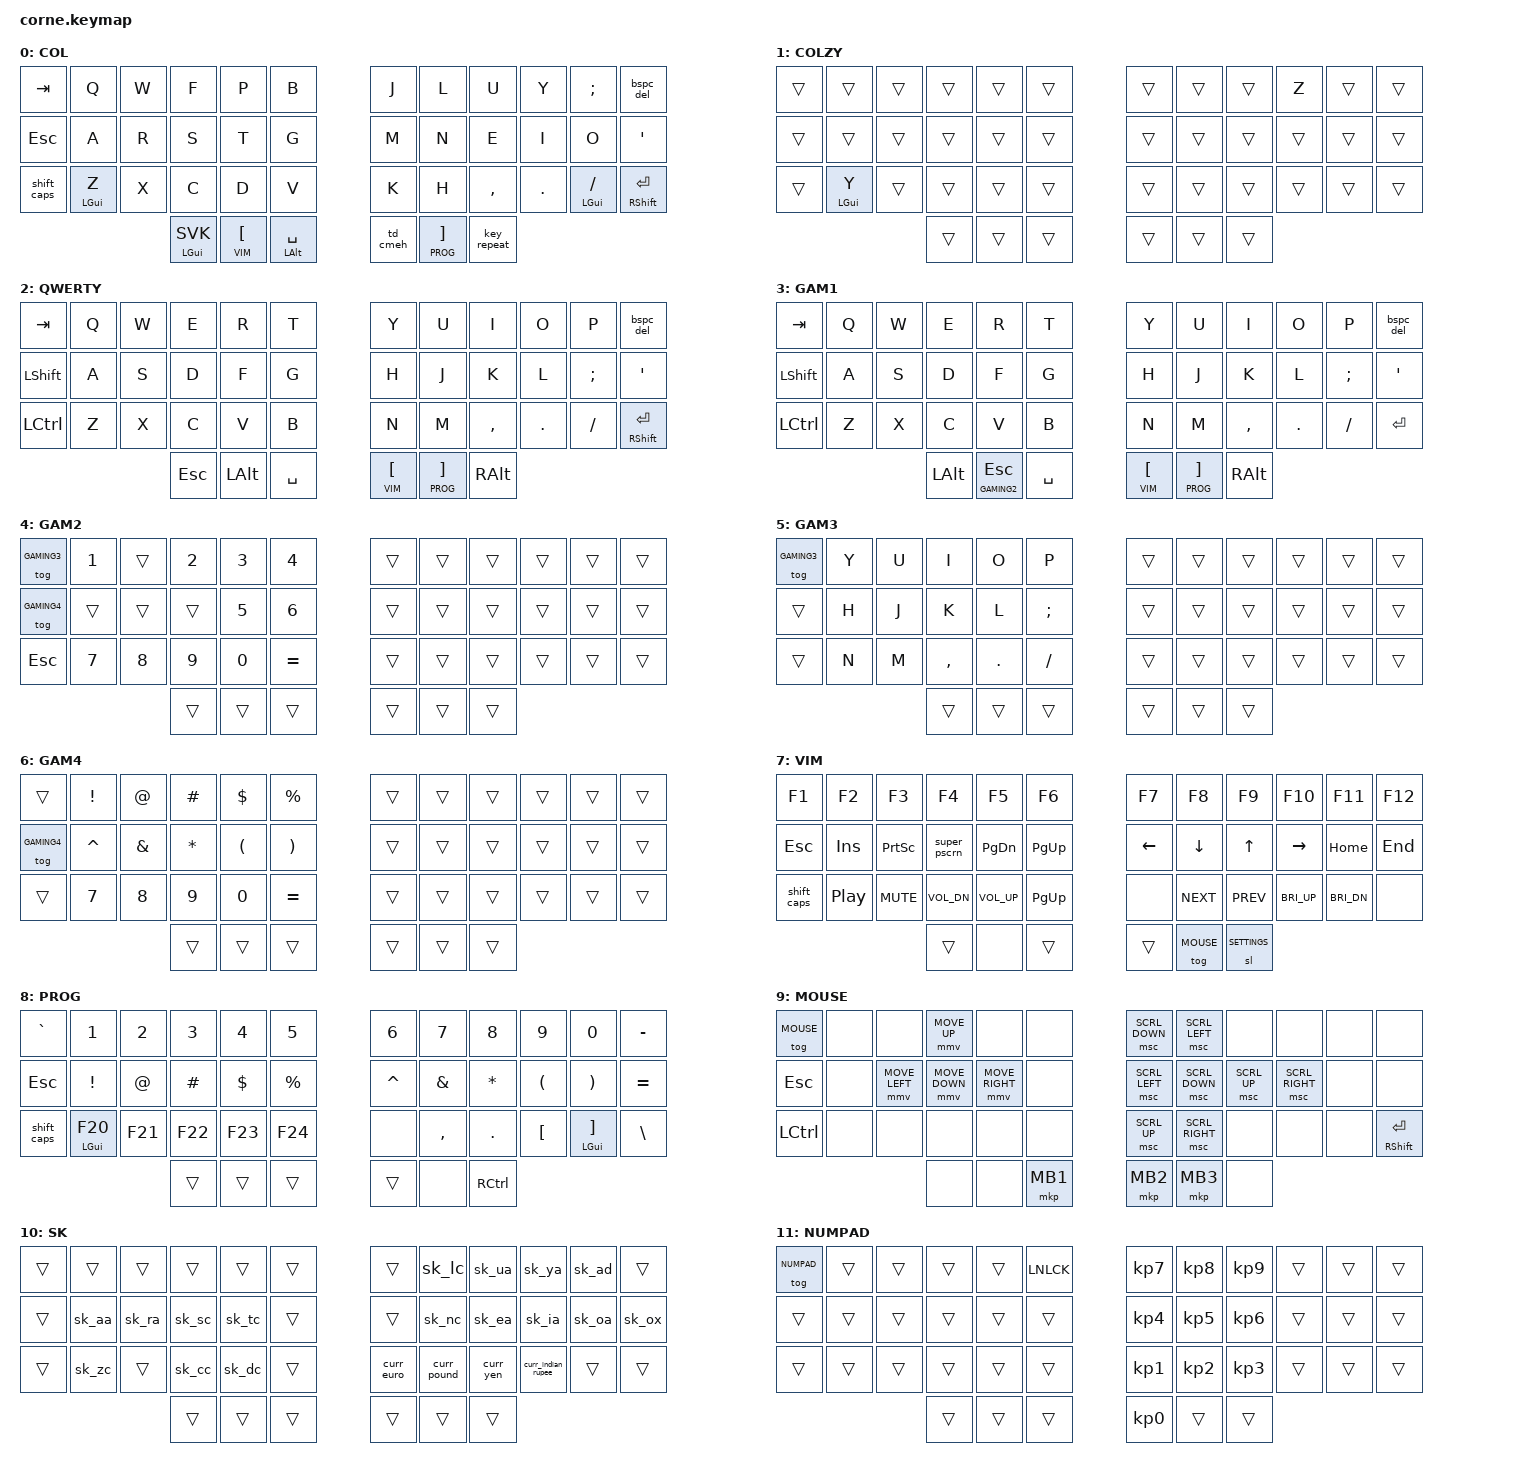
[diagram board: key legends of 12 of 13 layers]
/*
 * Copyright (c) 2020 The ZMK Contributors
 *
 * SPDX-License-Identifier: MIT
 */

/*
to visualize keymap:
https://nickcoutsos.github.io/keymap-editor/
https://github.com/caksoylar/keymap-drawer
to visualize battery without need of display
https://github.com/mh4x0f/zmkBATx
*/

#include <behaviors.dtsi>
#include <dt-bindings/zmk/keys.h>
#include <dt-bindings/zmk/bt.h>
#include <dt-bindings/zmk/outputs.h>
//#include <dt-bindings/zmk/ext_power.h>
#include <dt-bindings/zmk/outputs.h>

//#define ZMK_POINTING_DEFAULT_MOVE_VAL 1500  // default: 600
//#define ZMK_POINTING_DEFAULT_SCRL_VAL 20    // default: 10
#include <dt-bindings/zmk/pointing.h>

#define HOST_OS 1
#include "zmk-helpers/helper.h"
#include "zmk-helpers/unicode-chars/slovak.dtsi"
#include "zmk-helpers/unicode-chars/currency.dtsi"

#define COLEMAK  0
#define COLEMAKZ 1
#define QWERTY   2
#define GAMING   3
#define GAMING2  4
#define GAMING3  5
#define GAMING4  6
#define VIM      7
#define PROG     8
#define MOUSE    9
#define SVK      10
#define NUMPAD   11
#define SETTINGS 12


&mt {
      //tapping-term-ms = <1300>;
      flavor = "tap-preferred";
};

&sk {
    release-after-ms = <2500>;
    ignore-modifiers;
};

//&sl {
//    release-after-ms = <2000>;
//};

&key_repeat {
    usage-pages = <HID_USAGE_KEY HID_USAGE_CONSUMER>;
};

/ {
    behaviors {
        shift_caps: tap_dance_caps {
            compatible = "zmk,behavior-tap-dance";
            label = "TAP_DANCE_CAPS";
            #binding-cells = <0>;
            tapping-term-ms = <200>;
            bindings = <&kp LSHFT>, <&caps_word>;
        };

        td_gui: tap_dance_sticky_gui {
            compatible = "zmk,behavior-tap-dance";
            label = "TAP_DANCE_STICKY_GUI";
            #binding-cells = <0>;
            tapping-term-ms = <200>;
            bindings = <&kp LGUI>, <&sk LG(LALT)>, <&sk LG(LCTRL)>, <&sk LG(LSHIFT)>, <&sk RALT>;
        };

        td_cmeh: tap_dance_sticky_ctrl_meh {
            compatible = "zmk,behavior-tap-dance";
            label = "TAP_DANCE_STICKY_CTRL_MEH";
            #binding-cells = <0>;
            tapping-term-ms = <200>;
            bindings = <&kp LCTRL>, <&sk LG(LA(LCTRL))>, <&sk LG(LA(LS(LCTRL)))>, <&sk RALT>;
        };

        bspc_del: backspace_delete {
            compatible = "zmk,behavior-mod-morph";
            label = "BACKSPACE_DELETE";
            #binding-cells = <0>;
            bindings = <&kp BACKSPACE>, <&kp DELETE>;
            mods = <(MOD_LSFT|MOD_RSFT)>;
            keep-mods = <(MOD_RSFT)>;
        };

        mod_sl: hold_mod_sticky_layer {
            compatible = "zmk,behavior-hold-tap";
            label = "HOLD_MOD_STICKY_LAYER";
            #binding-cells = <2>;
            flavor = "hold-preferred";
            tapping-term-ms = <200>;
            bindings = <&kp>, <&sl>;
        };

        lm_sk: hold_layer_sticky_key {
            compatible = "zmk,behavior-hold-tap";
            label = "HOLD_LAYER_STICKY_KEY";
            #binding-cells = <2>;
            flavor = "hold-preferred";
            tapping-term-ms = <200>;
            bindings = <&mo>, <&sk>;
        };
    };




//SEE EXAMPLE: https://zmk.dev/docs/keymaps/behaviors/macros#layer--modifier
   macros {
        super_pscrn: super_pscrn {
            compatible = "zmk,behavior-macro";
            #binding-cells = <0>;
            bindings
                = <&macro_press &kp LGUI>
                , <&macro_tap &kp PSCRN>
                , <&macro_release &kp LGUI>
                ;
        };
   };

    //conditional_layers {
    //    compatible = "zmk,conditional-layers";
    //    to_qwerty_layer {
    //        if-layers = <COLEMAK>;
    //        then-layer = <QWERTY>;
    //    };
    //    to_colemak_layer {
    //        if-layers = <QWERTY>;
    //        then-layer = <COLEMAK>;
    //    };
    //};

    chosen {
      zmk,battery = &vbatt;
    };

    vbatt: vbatt {
        compatible = "zmk,battery-nrf-vddh";
        label = "VBATT";
    };

    keymap {
            compatible = "zmk,keymap";

                default_layer {
                        display-name = "COL";
                        bindings = <
   &kp TAB   &kp Q &kp W &kp F &kp P &kp B   &kp J &kp L  &kp U  &kp Y   &kp SEMI &bspc_del
   &kp ESC   &kp A &kp R &kp S &kp T &kp G   &kp M &kp N  &kp E  &kp I   &kp O    &kp SQT
   &shift_caps &mt LGUI Z &kp X &kp C &kp D &kp V   &kp K &kp H  &kp COMMA &kp DOT &mt LGUI FSLH &mt RSHIFT RET
             &mod_sl LGUI SVK &lt VIM LBKT &mt LALT SPACE   &td_cmeh &lt PROG RBKT &key_repeat
                        >;
                };




                colemak_qwertz_layer {
                        display-name = "COLZY";
                        bindings = <
   &trans &trans &trans &trans &trans &trans    &trans &trans &trans &kp Z &trans &trans
   &trans &trans &trans &trans &trans &trans    &trans &trans &trans &trans &trans &trans
   &trans &mt LGUI Y &trans &trans &trans &trans    &trans &trans &trans &trans &trans &trans
                     &trans &trans &trans    &trans &trans &trans
                        >;
                };




                qwerty_layer {
                        display-name = "QWERTY";
                        bindings = <
   &kp TAB   &kp Q &kp W &kp E &kp R &kp T   &kp Y &kp U  &kp I     &kp O   &kp P &bspc_del
   &kp LSHFT &kp A &kp S &kp D &kp F &kp G   &kp H &kp J  &kp K     &kp L   &kp SEMI &kp SQT
   &kp LCTRL &kp Z &kp X &kp C &kp V &kp B   &kp N &kp M  &kp COMMA &kp DOT &kp FSLH &mt RSHIFT RET
             &kp ESC &kp LALT &kp SPACE   &lt VIM LBKT &lt PROG RBKT &kp RALT
                        >;
                };




                gaming_layer {
                        display-name = "GAM1";
                        bindings = <
   &kp TAB   &kp Q &kp W &kp E &kp R &kp T   &kp Y &kp U  &kp I     &kp O   &kp P &bspc_del
   &kp LSHFT &kp A &kp S &kp D &kp F &kp G   &kp H &kp J  &kp K     &kp L   &kp SEMI &kp SQT
   &kp LCTRL &kp Z &kp X &kp C &kp V &kp B   &kp N &kp M  &kp COMMA &kp DOT &kp FSLH &kp RET
             &kp LALT &lt GAMING2 ESC &kp SPACE   &lt VIM LBKT &lt PROG RBKT &kp RALT
                        >;
                };
                gaming2_layer {
                        display-name = "GAM2";
                        bindings = <
   &tog GAMING3 &kp N1 &trans &kp N2 &kp N3 &kp N4    &trans &trans &trans &trans &trans &trans
   &tog GAMING4 &trans &trans &trans &kp N5 &kp N6    &trans &trans &trans &trans &trans &trans
   &kp ESC    &kp N7 &kp N8 &kp N9 &kp N0 &kp EQUAL    &trans &trans &trans &trans &trans &trans
                     &trans &trans &trans    &trans &trans &trans
                        >;
                };
                gaming3_layer {
                        display-name = "GAM3";
                        bindings = <
   &tog GAMING3 &kp Y &kp U  &kp I &kp O &kp P    &trans &trans &trans &trans &trans &trans
   &trans       &kp H &kp J  &kp K &kp L &kp SEMI         &trans &trans &trans &trans &trans &trans
   &trans       &kp N &kp M  &kp COMMA &kp DOT &kp FSLH   &trans &trans &trans &trans &trans &trans
                     &trans &trans &trans    &trans &trans &trans
                        >;
                };
                gaming4_layer {
                        display-name = "GAM4";
                        bindings = <
   &trans       &kp EXCL &kp AT &kp HASH &kp DLLR &kp PRCNT             &trans &trans &trans &trans &trans &trans
   &tog GAMING4 &kp CARET &kp AMPS &kp ASTRK &kp LPAR &kp RPAR    &trans &trans &trans &trans &trans &trans
   &trans       &kp N7 &kp N8 &kp N9 &kp N0 &kp EQUAL                   &trans &trans &trans &trans &trans &trans
                     &trans &trans &trans    &trans &trans &trans
                        >;
                };




                vim_layer {
                        display-name = "VIM";
                        bindings = <
   &kp F1 &kp F2 &kp F3 &kp F4 &kp F5 &kp F6      &kp F7 &kp F8 &kp F9 &kp F10 &kp F11 &kp F12
   &kp ESC &kp INS &kp PSCRN &super_pscrn &kp PG_DN &kp PG_UP    &kp LEFT &kp DOWN &kp UP &kp RIGHT &kp HOME &kp END
   &shift_caps &kp C_PP &kp C_MUTE &kp C_VOL_DN &kp C_VOL_UP &kp PG_UP    &none &kp C_NEXT &kp C_PREV &kp C_BRI_UP &kp C_BRI_DN &none
                    	     &trans &none &trans    &trans &tog MOUSE &sl SETTINGS
                        >;
                };




                programming_layer {
                        display-name = "PROG";
                        bindings = <
   &kp GRAVE &kp N1 &kp N2 &kp N3 &kp N4 &kp N5    &kp N6 &kp N7 &kp N8 &kp N9 &kp N0 &kp MINUS
   &kp ESC &kp EXCL &kp AT &kp HASH &kp DLLR &kp PRCNT    &kp CARET &kp AMPS &kp ASTRK &kp LPAR &kp RPAR &kp EQUAL
   &shift_caps  &mt LGUI F20 &kp F21 &kp F22 &kp F23 &kp F24    &none &kp COMMA &kp DOT &kp LBKT &mt LGUI RBKT &kp BSLH
                    	     &trans &trans &trans    &trans &none &kp RCTL
                        >;
                };




                mouse_layer {
                        display-name = "MOUSE";
                        bindings = <
   &tog MOUSE &none &none &mmv MOVE_UP &none &none    &msc SCRL_DOWN &msc SCRL_LEFT &none &none &none &none
   &kp ESC &none &mmv MOVE_LEFT &mmv MOVE_DOWN &mmv MOVE_RIGHT &none    &msc SCRL_LEFT &msc SCRL_DOWN &msc SCRL_UP &msc SCRL_RIGHT &none &none
   &kp LCTRL  &none &none &none &none &none    &msc SCRL_UP &msc SCRL_RIGHT &none &none &none &mt RSHIFT RET
                     &none &none &mkp MB1    &mkp MB2 &mkp MB3 &none
                        >;
                };




                slovak_layer {
                        display-name = "SK";
                        bindings = <
   &trans &trans &trans &trans &trans &trans    &trans &sk_lc &sk_ua &sk_ya &sk_ad &trans
   &trans &sk_aa &sk_ra &sk_sc &sk_tc &trans    &trans &sk_nc &sk_ea &sk_ia &sk_oa &sk_ox
   &trans &sk_zc &trans &sk_cc &sk_dc &trans    &curr_euro &curr_pound &curr_yen &curr_indian_rupee &trans &trans
                     &trans &trans &trans    &trans &trans &trans
                        >;
                };




                numpad_layer {
                        display-name = "NUMPAD";
                        bindings = <
   &tog NUMPAD &trans &trans &trans &trans &kp LNLCK    &kp KP_N7 &kp KP_N8 &kp KP_N9 &trans &trans &trans
   &trans &trans &trans &trans &trans &trans    &kp KP_N4 &kp KP_N5 &kp KP_N6 &trans &trans &trans
   &trans &trans &trans &trans &trans &trans    &kp KP_N1 &kp KP_N2 &kp KP_N3 &trans &trans &trans
                     &trans &trans &trans    &kp KP_N0 &trans &trans
                        >;
                };




                settings_layer {
                        display-name = "SET";
                        bindings = <
   &none &none &tog NUMPAD &tog QWERTY &tog GAMING &tog COLEMAKZ    &out OUT_TOG &none &none &none &none &none
   &bt BT_CLR &bt BT_SEL 0 &bt BT_SEL 1 &bt BT_SEL 2 &bt BT_SEL 3 &bt BT_SEL 4    &bt BT_DISC 0 &bt BT_DISC 1 &bt BT_DISC 2 &bt BT_DISC 3 &bt BT_DISC 4 &kp C_PWR
   &none &none &none &none &none &none    &none &none &none &none &none &soft_off
                     &none &none &none    &none &none &none
                        >;
                };




//                none_layer {
//                        bindings = <
//   &none &none &none &none &none &none    &none &none &none &none &none &none
//   &none &none &none &none &none &none    &none &none &none &none &none &none
//   &none &none &none &none &none &none    &none &none &none &none &none &none
//                     &none &none &none    &none &none &none
//                        >;
//                };




//                trans_layer {
//                        bindings = <
//   &trans &trans &trans &trans &trans &trans    &trans &trans &trans &trans &trans &trans
//   &trans &trans &trans &trans &trans &trans    &trans &trans &trans &trans &trans &trans
//   &trans &trans &trans &trans &trans &trans    &trans &trans &trans &trans &trans &trans
//                     &trans &trans &trans    &trans &trans &trans
//                        >;
//                };
        };
};
